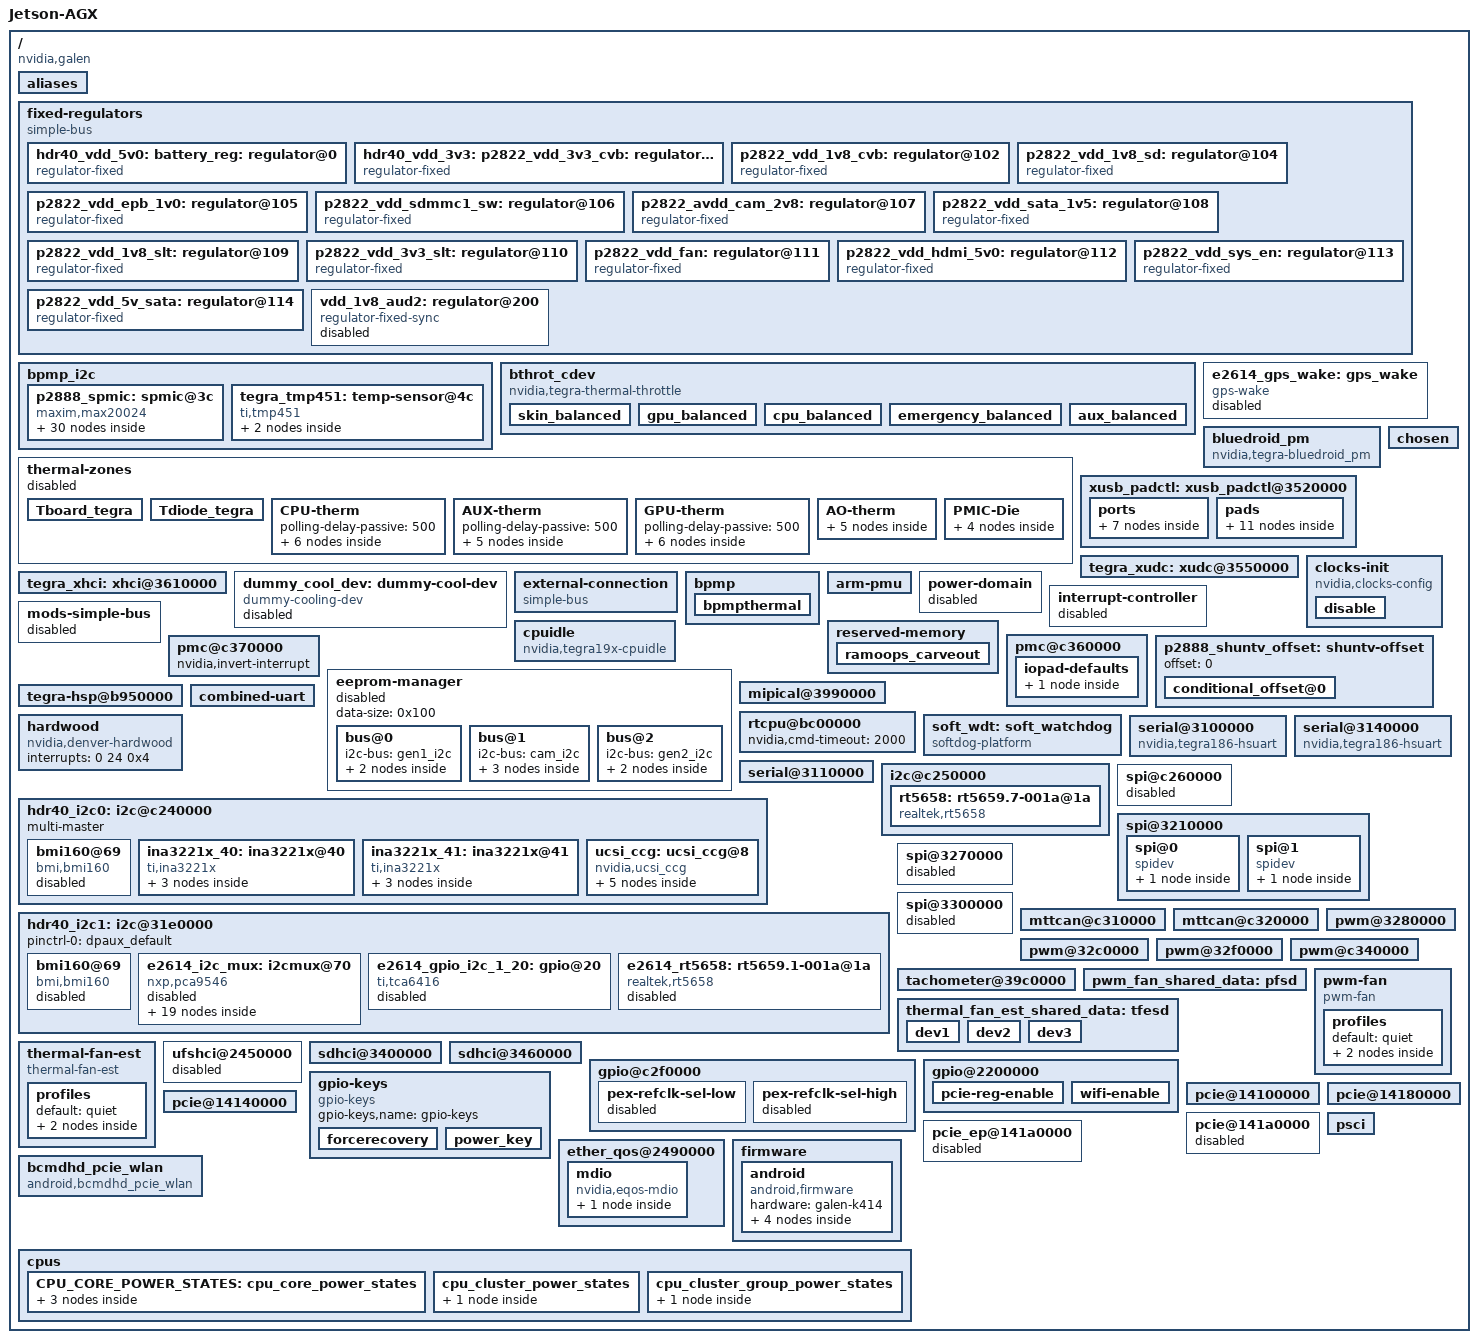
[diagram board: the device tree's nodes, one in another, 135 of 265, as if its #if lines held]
/*
 * Common include DTS file for CVM:P2888-0001 and CVB:P2822-0000 variants.
 *
 * Copyright (c) 2018-2020, NVIDIA CORPORATION.  All rights reserved.
 *
 * This program is free software; you can redistribute it and/or modify
 * it under the terms of the GNU General Public License as published by
 * the Free Software Foundation; version 2 of the License.
 *
 * This program is distributed in the hope that it will be useful, but WITHOUT
 * ANY WARRANTY; without even the implied warranty of MERCHANTABILITY or
 * FITNESS FOR A PARTICULAR PURPOSE.  See the GNU General Public License for
 * more details.
 */

#define TEMP_ALERT TEGRA194_MAIN_GPIO(H, 2)

#include <dt-bindings/types.h>
#include "dt-bindings/extcon-ids.h"
#include <dt-bindings/regulator/regulator.h>
#include "dt-bindings/gpio/tegra194-gpio.h"
#include <dt-bindings/clock/tegra194-clock.h>
#include <dt-bindings/pwm/pwm.h>
#include <dt-bindings/interrupt-controller/arm-gic.h>
#include <dt-bindings/interrupt-controller/irq.h>
#include <dt-bindings/thermal/thermal.h>
#include <dt-bindings/thermal/nvidia,tegra-thermal-throttle.h>
#include "dt-bindings/input/input.h"
#include <dt-bindings/display/tegra-dc.h>
#include <dt-bindings/display/tegra-panel.h>
#include <dt-bindings/mfd/max77620.h>
#include <dt-bindings/sound/rt5659.h>

/dts-v1/;

/memreserve/ 0x80000000 0x00010000;

#include <tegra194-soc/tegra194-soc-cvm.dtsi>

/ {
	model = "Jetson-AGX";
	compatible = "nvidia,tegra194";
	
	nvidia,dtsfilename = __FILE__;
	nvidia,dtbbuildtime = __DATE__, __TIME__;
	nvidia,fastboot-usb-vid = <0x0955>;
	nvidia,fastboot-usb-pid = <0xee1e>;
	model = "Jetson-AGX";
	compatible = "nvidia,galen", "nvidia,jetson-xavier", "nvidia,p2822-0000+p2888-0001", "nvidia,tegra194";

	#address-cells = <2>;
	#size-cells = <2>;

    aliases {
            rtc0 = &p2888_spmic;
            rtc1 = &tegra_rtc;
    };

	fixed-regulators {
		compatible = "simple-bus";
		device_type = "fixed-regulators";
		#address-cells = <1>;
		#size-cells = <0>;
		
		hdr40_vdd_5v0: battery_reg: regulator@0 {
			compatible = "regulator-fixed";
			reg = <0>;
			regulator-name = "vdd-ac-bat";
			regulator-min-microvolt = <5000000>;
			regulator-max-microvolt = <5000000>;
			regulator-always-on;
		};
		
		hdr40_vdd_3v3: p2822_vdd_3v3_cvb: regulator@101 {
			compatible = "regulator-fixed";
			reg = <101>;
			regulator-name = "vdd-3v3-cvb";
			regulator-min-microvolt = <3300000>;
			regulator-max-microvolt = <3300000>;
		};

		p2822_vdd_1v8_cvb: regulator@102 {
			compatible = "regulator-fixed";
			reg = <102>;
			regulator-name = "vdd-1v8-cvb";
			regulator-min-microvolt = <1800000>;
			regulator-max-microvolt = <1800000>;
		};

		p2822_vdd_1v8_sd: regulator@104 {
			compatible = "regulator-fixed";
			reg = <104>;
			regulator-name = "vdd-1v8-sd";
			regulator-min-microvolt = <1800000>;
			regulator-max-microvolt = <1800000>;
			gpio = <&tegra_main_gpio TEGRA194_MAIN_GPIO(A, 0) 0>;
			enable-active-high;
		};

		p2822_vdd_epb_1v0: regulator@105 {
			compatible = "regulator-fixed";
			reg = <105>;
			regulator-name = "vdd-epb-1v0";
			regulator-min-microvolt = <1000000>;
			regulator-max-microvolt = <1000000>;
			vin-supply = <&p2822_vdd_3v3_cvb>;
		};

		p2822_vdd_sdmmc1_sw: regulator@106 {
			compatible = "regulator-fixed";
			reg = <106>;
			regulator-name = "vdd-sdmmc1-sw";
			regulator-min-microvolt = <3300000>;
			regulator-max-microvolt = <3300000>;
			gpio = <&tegra_main_gpio TEGRA194_MAIN_GPIO(A, 0) 0>;
			enable-active-high;
		};

		p2822_avdd_cam_2v8: regulator@107 {
			compatible = "regulator-fixed";
			reg = <107>;
			regulator-name = "avdd-cam-2v8";
			regulator-min-microvolt = <2800000>;
			regulator-max-microvolt = <2800000>;
			gpio = <&tegra_main_gpio TEGRA194_MAIN_GPIO(N, 0) 0>;
			enable-active-high;
		};

		p2822_vdd_sata_1v5: regulator@108 {
			compatible = "regulator-fixed";
			reg = <108>;
			regulator-name = "vdd-sata-1v5";
			regulator-min-microvolt = <1500000>;
			regulator-max-microvolt = <1500000>;
		};

		p2822_vdd_1v8_slt: regulator@109 {
			compatible = "regulator-fixed";
			reg = <109>;
			regulator-name = "vdd-1v8-slt";
			regulator-min-microvolt = <1800000>;
			regulator-max-microvolt = <1800000>;
		};

		p2822_vdd_3v3_slt: regulator@110 {
			compatible = "regulator-fixed";
			reg = <110>;
			regulator-name = "vdd-3v3-slt";
			regulator-min-microvolt = <3300000>;
			regulator-max-microvolt = <3300000>;
		};

		p2822_vdd_fan: regulator@111 {
			compatible = "regulator-fixed";
			reg = <111>;
			regulator-name = "vdd-fan";
			regulator-min-microvolt = <5000000>;
			regulator-max-microvolt = <5000000>;
		};

		p2822_vdd_hdmi_5v0: regulator@112 {
			compatible = "regulator-fixed";
			reg = <112>;
			regulator-name = "vdd-hdmi-5v0";
			regulator-min-microvolt = <5000000>;
			regulator-max-microvolt = <5000000>;
			gpio = <&tegra_main_gpio TEGRA194_MAIN_GPIO(A, 3) 0>;
			enable-active-high;
		};

		p2822_vdd_sys_en: regulator@113 {
			compatible = "regulator-fixed";
			reg = <113>;
			regulator-name = "vdd_sys_en";
			regulator-min-microvolt = <1200000>;
			regulator-max-microvolt = <1200000>;
			gpio = <&tegra_main_gpio TEGRA194_MAIN_GPIO(M, 5) 0>;
			enable-active-high;
		};

		p2822_vdd_5v_sata: regulator@114 {
			compatible = "regulator-fixed";
			reg = <114>;
			regulator-name = "vdd-5v-sata";
			regulator-min-microvolt = <5000000>;
			regulator-max-microvolt = <5000000>;
			gpio = <&tegra_main_gpio TEGRA194_MAIN_GPIO(Z, 1) 0>;
			enable-active-high;
			vin-supply = <&battery_reg>;
		};
		
		vdd_1v8_aud2: regulator@200 {
			compatible = "regulator-fixed-sync";
			reg = <200>;
			regulator-name = "vdd-1v8-aud2";
			regulator-min-microvolt = <1800000>;
			regulator-max-microvolt = <1800000>;
			gpio = <&e2614_gpio_i2c_1_20 11 1>; /*DSPK EN*/
			enable-active-high;
			status = "disabled";
		};

	};

	bpmp_i2c {
		p2888_spmic: spmic@3c {
			compatible = "maxim,max20024";
			reg = <0x3c>;

			interrupt-parent = <&tegra_pm_irq>;
			interrupts = <0 TEGRA194_IRQ_PMIC_EXT_INTR IRQ_TYPE_NONE>;

			#interrupt-cells = <2>;
            interrupt-controller;

			gpio-controller;
			#gpio-cells = <2>;

			enable-clock32k-out;

			system-pmic-power-off;
			avoid-power-off-commands;

			hot-die-threshold-temp = <110000>;
			#thermal-sensor-cells = <0>;

			pinctrl-names = "default";
			pinctrl-0 = <&spmic_default>;

			spmic_default: pinmux@0 {
				pin_gpio0 {
					pins = "gpio0";
					function = "gpio";
				};

				pin_gpio1 {
					pins = "gpio1";
					function = "fps-out";
					active-fps-source = <MAX77620_FPS_SRC_DEF>;
				};

				pin_gpio2 {
					pins = "gpio2";
					function = "fps-out";
					active-fps-source = <MAX77620_FPS_SRC_DEF>;
				};

				pin_gpio3 {
					pins = "gpio3";
					function = "fps-out";
					active-fps-source = <MAX77620_FPS_SRC_DEF>;
				};

				pin_gpio4 {
					pins = "gpio4";
					function = "32k-out1";
					drive-push-pull = <1>;
				};

				pin_gpio6 {
					pins = "gpio6";
					function = "gpio";
					drive-push-pull = <1>;
				};

				pin_gpio7 {
					pins = "gpio7";
					function = "gpio";
					drive-push-pull = <0>;
				};
			};

			gpio_default {
				gpio-hog;
				output-high;
				gpios = <6 0 7 0>;
				label = "spmic-gpio6", "spmic-gpio7";
			};

			p2888_spmic_wdt: watchdog {
				wdt-boot-timeout = <32>;
				wdt-suspend-timeout = <120>;
				status = "disabled";
			};

			fps {
				#address-cells = <1>;
				#size-cells = <0>;

				fps0 {
					reg = <0>;
					fps-event-source = <MAX77620_FPS_EVENT_SRC_EN0>;
				};

				fps1 {
					reg = <1>;
					fps-event-source = <MAX77620_FPS_EVENT_SRC_EN1>;
					device-state-on-disabled-event = <MAX77620_FPS_INACTIVE_STATE_SLEEP>;
				};

				fps2 {
					reg = <2>;
					fps-event-source = <MAX77620_FPS_EVENT_SRC_EN0>;
				};
			};

			backup-battery {
				backup-battery-charging-current = <100>;
				backup-battery-charging-voltage = <3000000>;
				backup-battery-output-resister = <100>;
				status = "disabled";
			};

			regulators {
				in-ldo7-8-supply = <&p2888_spmic_sd2>;

				p2888_spmic_sd0: sd0 {
					regulator-name = "vdd-1v0";
					regulator-always-on;
					regulator-boot-on;
					regulator-init-mode = <REGULATOR_MODE_NORMAL>;
					active-fps-source = <MAX77620_FPS_SRC_DEF>;
					regulator-enable-ramp-delay = <3960>;
					regulator-disable-ramp-delay = <660>;
					ramp-rate-setting = <27500>;
					regulator-ramp-delay = <1100>;
				};

				p2888_spmic_sd1: sd1 {
					regulator-name = "vdd-1v8-hs";
					regulator-always-on;
					regulator-boot-on;
					regulator-init-mode = <REGULATOR_MODE_NORMAL>;
					active-fps-source = <MAX77620_FPS_SRC_DEF>;
					regulator-enable-ramp-delay = <3310>;
					regulator-disable-ramp-delay = <2000>;
					ramp-rate-setting = <27500>;
					regulator-ramp-delay = <550>;
				};

				p2888_spmic_sd2: sd2 {
					regulator-name = "vdd-1v8-ls";
					regulator-always-on;
					regulator-boot-on;
					regulator-init-mode = <REGULATOR_MODE_NORMAL>;
					active-fps-source = <MAX77620_FPS_SRC_DEF>;
					regulator-enable-ramp-delay = <3310>;
					regulator-disable-ramp-delay = <1970>;
					ramp-rate-setting = <27500>;
					regulator-ramp-delay = <550>;
				};

				p2888_spmic_sd3: sd3 {
					regulator-name = "vdd-1v8-ao";
					regulator-always-on;
					regulator-boot-on;
					regulator-init-mode = <REGULATOR_MODE_NORMAL>;
					active-fps-source = <MAX77620_FPS_SRC_DEF>;
					regulator-enable-ramp-delay = <2130>;
					regulator-disable-ramp-delay = <1970>;
					ramp-rate-setting = <27500>;
					regulator-ramp-delay = <350>;
				};

				p2888_spmic_sd4: sd4 {
					regulator-name = "vddio-ddr-1v1";
					regulator-always-on;
					regulator-boot-on;
					regulator-init-mode = <REGULATOR_MODE_NORMAL>;
					active-fps-source = <MAX77620_FPS_SRC_DEF>;
					regulator-enable-ramp-delay = <2650>;
					regulator-disable-ramp-delay = <1300>;
					ramp-rate-setting = <27500>;
					regulator-ramp-delay = <700>;
				};

				p2888_spmic_ldo0: ldo0 {
					regulator-name = "vdd-rtc";
					regulator-always-on;
					regulator-boot-on;
					active-fps-source = <MAX77620_FPS_SRC_DEF>;
					regulator-enable-ramp-delay = <160>;
					regulator-disable-ramp-delay = <4480>;
					ramp-rate-setting = <100000>;
					regulator-ramp-delay = <200>;
				};

				p2888_spmic_ldo1: ldo1 {
					regulator-name = "spmic-ldo1";
					active-fps-source = <MAX77620_FPS_SRC_DEF>;
					regulator-enable-ramp-delay = <2650>;
					regulator-disable-ramp-delay = <1300>;
					ramp-rate-setting = <100000>;
					regulator-ramp-delay = <1150>;
				};

				p2888_spmic_ldo2: ldo2 {
					regulator-name = "vdd-ao-3v3";
					regulator-always-on;
					regulator-boot-on;
					active-fps-source = <MAX77620_FPS_SRC_DEF>;
					regulator-enable-ramp-delay = <4670>;
					ramp-rate-setting = <100000>;
					regulator-ramp-delay = <1500>;
				};

				p2888_spmic_ldo3: ldo3 {
					regulator-name = "vddio-emmc-3v3";
					regulator-always-on;
					regulator-boot-on;
					active-fps-source = <MAX77620_FPS_SRC_DEF>;
					regulator-enable-ramp-delay = <4670>;
					ramp-rate-setting = <100000>;
					regulator-ramp-delay = <1500>;
				};

				p2888_spmic_ldo4: ldo4 {
					regulator-name = "spmic-ldo4";
					active-fps-source = <MAX77620_FPS_SRC_DEF>;
					regulator-enable-ramp-delay = <3310>;
					regulator-disable-ramp-delay = <1970>;
					ramp-rate-setting = <100000>;
					regulator-ramp-delay = <2200>;
				};

				p2888_spmic_ldo5: ldo5 {
					regulator-name = "vdd-usb-3v3";
					regulator-always-on;
					regulator-boot-on;
					active-fps-source = <MAX77620_FPS_SRC_DEF>;
					regulator-enable-ramp-delay = <4670>;
					ramp-rate-setting = <100000>;
					regulator-ramp-delay = <1500>;
				};

				p2888_spmic_ldo6: ldo6 {
					regulator-name = "vddio-sdmmc1-3v3";
					regulator-always-on;
					regulator-boot-on;
					active-fps-source = <MAX77620_FPS_SRC_DEF>;
					regulator-enable-ramp-delay = <4690>;
					ramp-rate-setting = <100000>;
					regulator-ramp-delay = <1500>;
				};

				p2888_spmic_ldo7: ldo7 {
					regulator-name = "vdd-csi-1v2";
					regulator-always-on;
					regulator-boot-on;
					active-fps-source = <MAX77620_FPS_SRC_DEF>;
					regulator-enable-ramp-delay = <3960>;
					regulator-disable-ramp-delay = <660>;
					ramp-rate-setting = <100000>;
					regulator-ramp-delay = <3350>;
				};

				p2888_spmic_ldo8: ldo8 {
					regulator-name = "spmic-ldo8";
					active-fps-source = <MAX77620_FPS_SRC_DEF>;
					regulator-enable-ramp-delay = <3960>;
					regulator-disable-ramp-delay = <660>;
					ramp-rate-setting = <100000>;
					regulator-ramp-delay = <2250>;
				};
				
			};
		};

		tegra_tmp451: temp-sensor@4c {
			status = "okay";
			#thermal-sensor-cells = <1>;
			compatible = "ti,tmp451";
			reg = <0x4c>;
			sensor-name = "tmp451-ext";
			supported-hwrev = <1>;
			offset = <(-38)>;
			conv-rate = <0x06>;
			extended-rage = <1>;

			interrupt-parent = <&tegra_main_gpio>;
			interrupts = <TEMP_ALERT IRQ_TYPE_LEVEL_LOW>;
			temp-alert-gpio = <&tegra_main_gpio TEMP_ALERT 0>;

			vdd-supply = <&p2822_vdd_1v8_slt>;

			/* vdd-supply configured in power tree */

			loc {
				/* set to maximum for not having local  shutdown */
				shutdown-limit = <107>;
			};
			ext {
				shutdown-limit = <109>;
			};
		};
	};

	bthrot_cdev {
		compatible = "nvidia,tegra-thermal-throttle";
		clocks = <&bpmp_clks TEGRA194_CLK_NAFLL_CLUSTER0>,
				<&bpmp_clks TEGRA194_CLK_NAFLL_CLUSTER1>,
				<&bpmp_clks TEGRA194_CLK_NAFLL_CLUSTER2>,
				<&bpmp_clks TEGRA194_CLK_NAFLL_CLUSTER3>,
				<&bpmp_clks TEGRA194_CLK_NAFLL_GPU>;
		clock-names = "cpu0", "cpu1", "cpu2", "cpu3", "gpu";
		skin_balanced {
			cdev-type = "skin-balanced";
			#cooling-cells = <2>;
			nvidia,throttle-clocks = <TEGRA_THROTTLE_CPU 200 0
						TEGRA_THROTTLE_GPU 400 0>;
		};
		gpu_balanced {
			cdev-type = "gpu-balanced";
			#cooling-cells = <2>;
			nvidia,cutoff = <1>;
			nvidia,throttle-clocks = <TEGRA_THROTTLE_CPU 400 0
						TEGRA_THROTTLE_GPU 400 0>;
		};
		cpu_balanced {
			cdev-type = "cpu-balanced";
			#cooling-cells = <2>;
			nvidia,throttle-clocks = <TEGRA_THROTTLE_CPU 200 0
						TEGRA_THROTTLE_GPU 300 365500000>;
		};
		emergency_balanced {
			cdev-type = "emergency-balanced";
			#cooling-cells = <2>;
			nvidia,throttle-clocks = <TEGRA_THROTTLE_CPU 10 38400000
						TEGRA_THROTTLE_GPU 10 25500000>;
		};
		aux_balanced {
			cdev-type = "aux-balanced";
			#cooling-cells = <2>;
			nvidia,cutoff = <1>;
			nvidia,throttle-clocks = <TEGRA_THROTTLE_CPU 400 0
						TEGRA_THROTTLE_GPU 400 0>;
		};
	};
	
	thermal-zones {
		status = "disabled";

		Tboard_tegra: Tboard_tegra {
			status = "okay";
			polling-delay = <0>;
			polling-delay-passive = <1000>;
			thermal-sensors = <&tegra_tmp451 0>;
		};

		Tdiode_tegra: Tdiode_tegra {
			status = "okay";
			polling-delay = <0>;
			polling-delay-passive = <1000>;
			thermal-sensors = <&tegra_tmp451 1>;
		};
		
		CPU-therm {
			status = "okay";
			polling-delay-passive = <500>;

			thermal-zone-params {
				governor-name = "step_wise";
			};

			trips {
				trip_critical {
					temperature = <95500>;
					type = "critical";
					hysteresis = <0>;
					writable;
				};
				trip_bthrot {
					temperature = <90000>;
					type = "passive";
					hysteresis = <0>;
					writable;
				};
			};
			cooling-maps {
				map0 {
					trip = <&{/thermal-zones/CPU-therm/trips/trip_bthrot}>;
					cdev-type = "cpu-balanced";
					cooling-device = <&{/bthrot_cdev/cpu_balanced} THERMAL_NO_LIMIT THERMAL_NO_LIMIT>;
				};
			};
			
			trips {
				MAKE_EQOS_TRIP(m40, -40000, 5000);
				MAKE_EQOS_TRIP(m5, -5000, 5000);
				MAKE_EQOS_TRIP(p30, 30000, 5000);
				MAKE_EQOS_TRIP(p65, 65000, 5000);
				MAKE_EQOS_TRIP(p100, 100000, 5000);
			};

			cooling-maps {
				MAP_EQOS(m40, 1);
				MAP_EQOS(m5, 2);
				MAP_EQOS(p30, 3);
				MAP_EQOS(p65, 4);
				MAP_EQOS(p100, 5);
			};
			
		};

		AUX-therm {
			status = "okay";
			polling-delay-passive = <500>;
			trips {
				trip_critical {
					temperature = <94500>;
					type = "critical";
					hysteresis = <0>;
					writable;
				};

				trip_bthrot {
					temperature = <89000>;
					type = "passive";
					hysteresis = <0>;
					writable;
				};
			};
			cooling-maps {
				map0 {
					trip = <&{/thermal-zones/AUX-therm/trips/trip_bthrot}>;
					cdev-type = "aux-balanced";
					cooling-device = <&{/bthrot_cdev/aux_balanced} THERMAL_NO_LIMIT THERMAL_NO_LIMIT>;
				};
			};
		};

		GPU-therm {
			status = "okay";
			polling-delay-passive = <500>;

			thermal-zone-params {
				governor-name = "step_wise";
			};

			trips {
				trip_critical {
					temperature = <98000>;
					type = "critical";
					hysteresis = <0>;
					writable;
				};
				trip_bthrot {
					temperature = <92500>;
					type = "passive";
					hysteresis = <0>;
					writable;
				};
			};
			cooling-maps {
				map0 {
					trip = <&{/thermal-zones/GPU-therm/trips/trip_bthrot}>;
					cdev-type = "gpu-balanced";
					cooling-device = <&{/bthrot_cdev/gpu_balanced} THERMAL_NO_LIMIT THERMAL_NO_LIMIT>;
				};
			};

		};

		AO-therm {
			status = "okay";

			thermal-zone-params {
				governor-name = "step_wise";
			};

			trips {
				trip_dram_refresh {
					temperature = <85000>;
					type = "active";
					hysteresis = <3000>;
					writable;
				};
			};
			cooling-maps {
				map0 {
					trip = <&{/thermal-zones/AO-therm/trips/trip_dram_refresh}>;
					cdev-type = "bwmgr-therm-handler";
					cooling-device = <&bwmgr THERMAL_NO_LIMIT THERMAL_NO_LIMIT>;
				};
			};
		};
		
		PMIC-Die {
			polling-delay = <0>; /* milliseconds */
			polling-delay-passive = <0>; /* milliseconds */

			thermal-sensors = <&p2888_spmic>;
			trips {
				die_temp_thresh: hot-die {
					temperature = <120000>;
					type = "active";
					hysteresis = <0>;
				};
			};

			cooling-maps {
				map0 {
					trip = <&die_temp_thresh>;
					cooling-device = <&{/bthrot_cdev/emergency_balanced}
							THERMAL_NO_LIMIT THERMAL_NO_LIMIT>;
					contribution = <100>;
					cdev-type = "emergency-balanced";
				};
			};
		};
		
	};

	e2614_gps_wake: gps_wake {
		compatible = "gps-wake";
		gps-enable-gpio = <&e2614_gpio_i2c_1_20 8 0>;
		gps-wakeup-gpio = <&tegra_main_gpio TEGRA194_AON_GPIO(AA, 0) 0>;
		status = "disabled";
	};

	bluedroid_pm {
		compatible = "nvidia,tegra-bluedroid_pm";
		bluedroid_pm,reset-gpio = <&tegra_main_gpio TEGRA194_MAIN_GPIO(M, 6) 0>;
		bluedroid_pm,host-wake-gpio = <&tegra_main_gpio TEGRA194_MAIN_GPIO(Y, 0) 0>;
		bluedroid_pm,ext-wake-gpio = <&tegra_main_gpio TEGRA194_MAIN_GPIO(M, 7) 0>;
		interrupt-parent = <&tegra_main_gpio>;
		interrupts = <TEGRA194_MAIN_GPIO(Y, 0) 0x01>;
	};

#if TEGRA_XUSB_PADCONTROL_VERSION >= DT_VERSION_2
	xusb_padctl: xusb_padctl@3520000 {
		status = "okay";
		pex_dvdd-supply = <&p2888_spmic_sd0>;
		pex_hvdd-supply = <&p2888_spmic_sd1>;
		pex_pll_hvdd-supply = <&p2888_spmic_sd1>;
		vclamp_usb-supply = <&p2888_spmic_sd3>;
		avdd_usb-supply = <&p2888_spmic_ldo5>;
		avdd_pll_nvhs_eutmip-supply = <&p2888_spmic_sd1>;
		ports {
			usb2-0 {
				vbus-supply = <&battery_reg>;
			};
			usb2-1 {
				vbus-supply = <&battery_reg>;
			};
			usb2-2 {
				vbus-supply = <&battery_reg>;
			};
			usb2-3 {
				vbus-supply = <&p2822_vdd_5v_sata>;
			};
		};
		
		pads {
			usb2 {
				lanes {
					usb2-0 {
						nvidia,function = "xusb";
						status = "okay";
					};
					usb2-1 {
						nvidia,function = "xusb";
						status = "okay";
					};
					usb2-2 {
						nvidia,function = "xusb";
						status = "okay";
					};
					usb2-3 {
						nvidia,function = "xusb";
						status = "okay";
					};
				};
			};
			usb3 {
				lanes {
					usb3-0 {
						nvidia,function = "xusb";
						status = "okay";
					};
					usb3-2 {
						nvidia,function = "xusb";
						status = "okay";
					};
					usb3-3 {
						nvidia,function = "xusb";
						status = "okay";
					};
				};
			};
		};

		ports {
			usb2-0 {
				mode = "otg";
				status = "okay";
			};
			usb2-1 {
				mode = "host";
				status = "okay";
			};
			usb2-2 {
				mode = "host";
				status = "okay";
			};
			usb2-3 {
				mode = "host";
				status = "okay";
			};
			usb3-0 {
				nvidia,usb2-companion = <1>;
				status = "okay";
			};
			usb3-2 {
				nvidia,usb2-companion = <0>;
				status = "okay";
			};
			usb3-3 {
				nvidia,usb2-companion = <3>;
				nvidia,usb3-gen1-only= <1>;
				status = "okay";
			};
		};
	};
#endif

	tegra_xudc: xudc@3550000 {
		avdd-usb-supply = <&p2888_spmic_ldo5>;
		extcon-cables = <&typec_port0 0>;
		extcon-cable-names = "vbus";
		#extcon-cells = <1>;
#if TEGRA_XUSB_PADCONTROL_VERSION >= DT_VERSION_2
		phys = <&{/xusb_padctl@3520000/pads/usb2/lanes/usb2-0}>,
			<&{/xusb_padctl@3520000/pads/usb3/lanes/usb3-2}>;
		phy-names = "usb2", "usb3";
		nvidia,xusb-padctl = <&xusb_padctl>;
#endif
		nvidia,boost_cpu_freq = <1200>;
		status = "okay";
	};

	tegra_xhci: xhci@3610000 {
		extcon-cables = <&typec_port0 1>;
		extcon-cable-names = "id";
		#extcon-cells = <1>;
#if TEGRA_XUSB_PADCONTROL_VERSION >= DT_VERSION_2
		phys = <&{/xusb_padctl@3520000/pads/usb2/lanes/usb2-0}>,
			<&{/xusb_padctl@3520000/pads/usb2/lanes/usb2-1}>,
			<&{/xusb_padctl@3520000/pads/usb2/lanes/usb2-3}>,
			<&{/xusb_padctl@3520000/pads/usb2/lanes/usb2-2}>,
			<&{/xusb_padctl@3520000/pads/usb3/lanes/usb3-2}>,
			<&{/xusb_padctl@3520000/pads/usb3/lanes/usb3-0}>,
			<&{/xusb_padctl@3520000/pads/usb3/lanes/usb3-3}>;
		phy-names = "usb2-0", "usb2-1", "usb2-3", "usb2-2",
			"usb3-2", "usb3-0", "usb3-3";
		nvidia,xusb-padctl = <&xusb_padctl>;
#endif
		status = "okay";
	};
	
	chosen {
		bootargs ="console=ttyTCU0,115200";
		board-has-eeprom;
	};
	
	clocks-init {
		compatible = "nvidia,clocks-config";
		status = "okay";
		disable {
			clocks = <&aon_clks TEGRA194_CLK_PLLAON>,
				<&bpmp_clks TEGRA194_CLK_CAN1>,
				<&bpmp_clks TEGRA194_CLK_CAN2>;
		};
	};

	dummy_cool_dev: dummy-cool-dev {
		compatible = "dummy-cooling-dev";
		#cooling-cells = <2>; /* min followed by max */
		status = "disabled";
	};

	external-connection {
		compatible = "simple-bus";
		device_type = "external-connection";
		#address-cells = <1>;
		#size-cells = <0>;
	};

	bpmp {
		bpmpthermal {
			status = "okay";
		};
	};

	arm-pmu {
		status = "okay";
	};

	power-domain {
		status = "disabled";
	};

	interrupt-controller {
		status = "disabled";
	};

	mods-simple-bus {
		status = "disabled";
	};

	cpuidle {
		compatible = "nvidia,tegra19x-cpuidle";
		status = "okay";
	};

	reserved-memory {
		ramoops_carveout {
			status = "okay";
		};
	};

	/* Power Management Controller */
	pmc@c360000 {
		iopad-defaults {
			sdmmc-io-pads {
				pins = "sdmmc1-hv", "sdmmc3-hv";
				nvidia,enable-voltage-switching;
			};
		};
	};

	pmc@c370000 {
		nvidia,invert-interrupt;
	};

	eeprom-manager {
		status = "disabled";
		data-size = <0x100>;
		bus@0 {
			i2c-bus = <&gen1_i2c>;
			eeprom@0 {
				slave-address = <0x50>;
				label = "cvm";
			};
			eeprom@1 {
				slave-address = <0x56>;
			};
		};
		bus@1 {
			i2c-bus = <&cam_i2c>;
			eeprom@0 {
				slave-address = <0x54>;
			};
			eeprom@1 {
				slave-address = <0x57>;
			};
			eeprom@2 {
				slave-address = <0x52>;
			};
		};
		bus@2 {
			i2c-bus = <&gen2_i2c>;
			eeprom@0 {
				slave-address = <0x52>;
				label = "cvm";
			};
			eeprom@1 {
				slave-address = <0x50>;
			};
		};
		
	};

	p2888_shuntv_offset: shuntv-offset {
		offset = <0>;
		conditional_offset@0 {
			shunt_volt_start = <0xFFFFFFD8>;
			shunt_volt_end = <0xFFFFFFD8>;
			offset = <40>;
		};
	};

	mipical@3990000 {
		status = "okay";
	};

	tegra-hsp@b950000 {
		status = "okay";
	};

	rtcpu@bc00000 {
		status = "okay";
		nvidia,cmd-timeout = <2000>;
	};

	hardwood {
		compatible = "nvidia,denver-hardwood";
		interrupts = <0 24 0x4>;
	};

	soft_wdt:soft_watchdog {
		compatible = "softdog-platform";
		status = "okay";
	};
	
/* uart-configure */
	combined-uart {
		console-port;
		combined-uart;
		status = "okay";
	};
	
	serial@3100000 {
		compatible = "nvidia,tegra186-hsuart";
		status = "okay";
	};

	serial@3140000 {
		compatible = "nvidia,tegra186-hsuart";
		status = "okay";
	};

	serial@3110000 {
		status = "okay";
	};
	
	
/* i2c-configure */
	i2c@c250000 {
		rt5658: rt5659.7-001a@1a {
			compatible = "realtek,rt5658";
			reg = <0x1a>;

			realtek,jd-src = <RT5659_JD_NULL>;
			realtek,dmic1-data-pin = <RT5659_DMIC1_NULL>;
			realtek,dmic2-data-pin = <RT5659_DMIC2_NULL>;

			gpios = <&tegra_main_gpio TEGRA194_MAIN_GPIO(S, 5) 0>;

			status = "okay";
		};
	};
	
	hdr40_i2c0: i2c@c240000 {
		multi-master;
		
		bmi160@69 {
			compatible = "bmi,bmi160";
			reg = <0x69>;
			interrupt-parent = <&tegra_aon_gpio>;
			interrupts = <TEGRA194_AON_GPIO(AA, 2) GPIO_ACTIVE_LOW>;
			accelerometer_matrix    = [01 00 00 00 01 00 00 00 01];
			gyroscope_matrix        = [01 00 00 00 01 00 00 00 01];
			accelerometer_delay_us_min = <1250>;
			gyroscope_delay_us_min = <1250>;
			status = "disabled";
		};
		
		ina3221x_40: ina3221x@40 {
			compatible = "ti,ina3221x";
			reg = <0x40>;
			ti,trigger-config = <0x7003>;
			ti,continuous-config = <0x7c07>;
			ti,enable-forced-continuous;
			#address-cells = <1>;
			#size-cells = <0>;
			#io-channel-cells = <1>;
			channel@0 {
				reg = <0x0>;
				ti,rail-name = "GPU";
				ti,shunt-resistor-mohm = <5>;
				shunt-volt-offset-uv = <&p2888_shuntv_offset>;
			};
			channel@1 {
				reg = <0x1>;
				ti,rail-name = "CPU";
				ti,shunt-resistor-mohm = <5>;
				shunt-volt-offset-uv = <&p2888_shuntv_offset>;
			};
			channel@2 {
				reg = <0x2>;
				ti,rail-name = "SOC";
				ti,shunt-resistor-mohm = <5>;
				shunt-volt-offset-uv = <&p2888_shuntv_offset>;
			};
		};
		
		ina3221x_41: ina3221x@41 {
			compatible = "ti,ina3221x";
			reg = <0x41>;
			ti,trigger-config = <0x7003>;
			ti,continuous-config = <0x7c07>;
			ti,enable-forced-continuous;
			#address-cells = <1>;
			#size-cells = <0>;
			#io-channel-cells = <1>;
			channel@0 {
				reg = <0x0>;
				ti,rail-name = "CV";
				ti,shunt-resistor-mohm = <5>;
				shunt-volt-offset-uv = <&p2888_shuntv_offset>;
			};
			channel@1 {
				reg = <0x1>;
				ti,rail-name = "VDDRQ";
				ti,shunt-resistor-mohm = <5>;
				shunt-volt-offset-uv = <&p2888_shuntv_offset>;
			};
			channel@2 {
				reg = <0x2>;
				ti,rail-name = "SYS5V";
				ti,shunt-resistor-mohm = <5>;
				shunt-volt-offset-uv = <&p2888_shuntv_offset>;
			};
		};
		
		ucsi_ccg: ucsi_ccg@8 {
			compatible = "nvidia,ucsi_ccg";
			reg = <0x08>;
			ccg,irqflags = <IRQF_TRIGGER_LOW>;
			interrupt-parent = <&tegra_aon_gpio>;
			interrupts = <TEGRA194_AON_GPIO(BB, 2) 0>;
			wakeup-source;
			status = "okay";
			typec-extcon {
				typec_port0: port-0 {
					status = "okay";
					#extcon-cells = <1>;
				};
				typec_port1: port-1 {
					status = "okay";
					#extcon-cells = <1>;
				};
			};
			typec-pd {
				typec_pd: pd {
					status = "okay";
					#extcon-cells = <1>;
				};
			};
		};
	};

	hdr40_i2c1: i2c@31e0000 {
		pinctrl-names = "default";
		pinctrl-0 = <&dpaux_default>;
		
		bmi160@69 {
			compatible = "bmi,bmi160";
			reg = <0x69>;
			accelerometer_matrix    = [01 00 00 00 01 00 00 00 01];
			gyroscope_matrix        = [01 00 00 00 01 00 00 00 01];
			status = "disabled";
		};

		e2614_i2c_mux: i2cmux@70 {
			compatible = "nxp,pca9546";
			reg = <0x70>;
			#address-cells = <1>;
			#size-cells = <0>;
			vcc-pullup-supply = <&battery_reg>;
			status = "disabled";
			
			i2c@0 {
				reg = <0>;
				i2c-mux,deselect-on-exit;
				#address-cells = <1>;
				#size-cells = <0>;
				e2614_tas2552_r:tas2552.9-0040@40 {
					compatible = "ti,tas2552";
					reg = <0x40>;
					vbat-supply = <&battery_reg>;
					avdd-supply = <&vdd_1v8_aud2>;
					tas2552,pdm_edge_select = <0>;
				};
				e2614_tas2552_l:tas2552.9-0041@41 {
                                        compatible = "ti,tas2552";
                                        reg = <0x41>;
                                        vbat-supply = <&battery_reg>;
                                        avdd-supply = <&vdd_1v8_aud2>;
					tas2552,pdm_edge_select = <1>;
                                };
			};
			
			i2c@1 {
				reg = <1>;
				i2c-mux,deselect-on-exit;
				#address-cells = <1>;
				#size-cells = <0>;
				ina3221x@40 {
					compatible = "ti,ina3221x";
					reg = <0x40>;
					ti,trigger-config = <0x7003>;
					ti,continuous-config = <0x7c07>;
					ti,enable-forced-continuous;
					#address-cells = <1>;
					#size-cells = <0>;
					channel@0 {
						reg = <0x0>;
						ti,rail-name = "VDD_5V";
						ti,shunt-resistor-mohm = <10>;
					};
					channel@1 {
						reg = <0x1>;
						ti,rail-name = "VDD_3V3";
						ti,shunt-resistor-mohm = <10>;
					};
					channel@2 {
						reg = <0x2>;
						ti,rail-name = "VDD_1V8";
						ti,shunt-resistor-mohm = <1>;
					};
				};
				ina3221x@41 {
					compatible = "ti,ina3221x";
					reg = <0x41>;
					ti,trigger-config = <0x7003>;
					ti,continuous-config = <0x7c07>;
					ti,enable-forced-continuous;
					#address-cells = <1>;
					#size-cells = <0>;
					channel@0 {
						reg = <0x0>;
						ti,rail-name = "VDD_5V_AUD";
						ti,shunt-resistor-mohm = <1>;
					};
					channel@1 {
						reg = <0x1>;
						ti,rail-name = "VDD_3V3_AUD";
						ti,shunt-resistor-mohm = <10>;
					};
					channel@2 {
						reg = <0x2>;
						ti,rail-name = "VDD_1V8_AUD";
						ti,shunt-resistor-mohm = <10>;
					};
				};
				ina3221x@42 {
					compatible = "ti,ina3221x";
					reg = <0x42>;
					ti,trigger-config = <0x7003>;
					ti,continuous-config = <0x7c07>;
					ti,enable-forced-continuous;
					#address-cells = <1>;
					#size-cells = <0>;
					channel@0 {
						reg = <0x0>;
						ti,rail-name = "VDD_3V3_GPS";
						ti,shunt-resistor-mohm = <10>;
					};
					channel@1 {
						reg = <0x1>;
						ti,rail-name = "VDD_3V3_NFC";
						ti,shunt-resistor-mohm = <10>;
					};
					channel@2 {
						reg = <0x2>;
						ti,rail-name = "VDD_3V3_GYRO";
						ti,shunt-resistor-mohm = <10>;
					};
				};
			};
			
			i2c@2 {
				reg = <2>;
				i2c-mux,deselect-on-exit;
				#address-cells = <1>;
				#size-cells = <0>;
			};
			
			i2c@3 {
				reg = <3>;
				i2c-mux,deselect-on-exit;
				#address-cells = <1>;
				#size-cells = <0>;
				e2614_rt5658_i2c3: rt5659.12-001a@1a {
					compatible = "realtek,rt5658";
					reg = <0x1a>;
					status = "disabled";

					/* gpio for jack detection */
					gpios = <&tegra_main_gpio TEGRA194_MAIN_GPIO(R, 0) 0>;

					/* refer include/sound/rt5659.h for the values to be used */
					realtek,jd-src = <1>; /* RT5659_JD3 */
					realtek,dmic1-data-pin = <2>; /* RT5659_DMIC1_DATA_GPIO5 */
				};
			};
		};

		e2614_gpio_i2c_1_20: gpio@20 {
			compatible = "ti,tca6416";
			reg = <0x20>;
			gpio-controller;
			#gpio-cells = <2>;
			vcc-supply = <&battery_reg>;
			status = "disabled";
		};

		e2614_rt5658: rt5659.1-001a@1a {
			compatible = "realtek,rt5658";
			reg = <0x1a>;
			status = "disabled";

			/* gpio for jack detection */
			gpios = <&tegra_main_gpio TEGRA194_MAIN_GPIO(R, 0) 0>;

			/* refer include/sound/rt5659.h for the values to be used */
			realtek,jd-src = <1>; /* RT5659_JD3 */
			realtek,dmic1-data-pin = <2>; /* RT5659_DMIC1_DATA_GPIO5 */
		};

		i2cmux@70 {
			vcc-supply = <&p2822_vdd_3v3_cvb>;
			i2c@0 {
				tas2552.9-0040@40 {
					iovdd-supply = <&p2822_vdd_3v3_cvb>;
				};
				tas2552.9-0041@41 {
					iovdd-supply = <&p2822_vdd_3v3_cvb>;
                                };
			};
		};

	};
	
/* spi-configure */
	spi@c260000 {
        clocks = <&bpmp_clks TEGRA194_CLK_SPI2>,
                 <&bpmp_clks TEGRA194_CLK_OSC>;
		status = "disabled";
	};

	spi@3210000 {
		status = "okay";
		spi@0 {
			compatible = "spidev";
			reg = <0x0>;
			spi-max-frequency = <33000000>;
			controller-data {
				nvidia,enable-hw-based-cs;
				nvidia,rx-clk-tap-delay = <0x11>;
			};
		};
		spi@1 {
			compatible = "spidev";
			reg = <0x1>;
			spi-max-frequency = <33000000>;
			controller-data {
				nvidia,enable-hw-based-cs;
				nvidia,rx-clk-tap-delay = <0x11>;
			};
		};
	};

	spi@3270000 {
		status = "disabled";
	};

	spi@3300000 {
		status = "disabled";
	};

/* can-configure */
    mttcan@c310000 {
		pll_source = "osc";
            clocks = <&bpmp_clks TEGRA194_CLK_CAN1_CORE>,
                    <&bpmp_clks TEGRA194_CLK_CAN1_HOST>,
                    <&bpmp_clks TEGRA194_CLK_CAN1>,
                    <&bpmp_clks TEGRA194_CLK_OSC>;
	 clock-names = "can_core", "can_host","can", "osc";
	 status = "okay";
    };

    mttcan@c320000 {
		pll_source = "osc";
            clocks = <&bpmp_clks TEGRA194_CLK_CAN2_CORE>,
                    <&bpmp_clks TEGRA194_CLK_CAN2_HOST>,
                    <&bpmp_clks TEGRA194_CLK_CAN2>,
                    <&bpmp_clks TEGRA194_CLK_OSC>;
		clock-names = "can_core", "can_host","can", "osc";
		status = "okay";
    };
	
/* pwm-configure */
	pwm@3280000 {
		status = "okay";
	};

	pwm@32c0000 {
		status = "okay";
	};

	pwm@32f0000 {
		status = "okay";
	};
	
	pwm@c340000 {
		status = "okay";
	};

	tachometer@39c0000 {
		status = "okay";
	};

	pwm_fan_shared_data: pfsd {
		num_resources = <0>;
		secret = <47>;
		active_steps = <10>;
		active_rpm = <0 1000 2000 3000 4000 5000 6000 7000 10000 11000>;
		rpm_diff_tolerance = <2>;
		active_rru = <40 2 1 1 1 1 1 1 1 1>;
		active_rrd = <40 2 1 1 1 1 1 1 1 1>;
		state_cap_lookup = <2 2 2 2 3 3 3 4 4 4>;
		pwm_period = <45334>;
		pwm_id = <4>;
		pwm_polarity = <PWM_POLARITY_NORMAL>;
		suspend_state = <0>;
		step_time = <100>; /* mesecs */
		state_cap = <7>;
		active_pwm_max = <256>;
		tach_period = <1000>;
		pwm_gpio = <&tegra_aon_gpio TEGRA194_AON_GPIO(CC, 4) GPIO_ACTIVE_LOW>;
	};

	pwm-fan {
		compatible = "pwm-fan";
		status = "okay";
		#pwm-cells = <1>;
		pwms = <&tegra_pwm4 0 45334>;
		vdd-fan-supply = <&p2822_vdd_fan>;
		shared_data = <&pwm_fan_shared_data>;
		profiles {
			default = "quiet";
			quiet {
				state_cap = <4>;
				active_pwm = <0 77 120 160 255 255 255 255 255 255>;
			};
			cool {
				state_cap = <4>;
				active_pwm = <0 77 120 160 255 255 255 255 255 255>;
			};
		};
	};

	thermal_fan_est_shared_data: tfesd {
		secret = <37>;
		toffset = <0>;
		polling_period = <1100>;
		ndevs = <3>;
		cdev_type = "pwm-fan";
		tzp_governor_name = "pid_thermal_gov";

		dev1 {
			dev_data = "CPU-therm";
			coeffs = <30 0 0 0 0 0 0 0 0 0 0 0 0 0 0 0 0 0 0 0>;
		};
		dev2 {
			dev_data = "GPU-therm";
			coeffs = <30 0 0 0 0 0 0 0 0 0 0 0 0 0 0 0 0 0 0 0>;
		};
		dev3 {
			dev_data = "AUX-therm";
			coeffs = <40 0 0 0 0 0 0 0 0 0 0 0 0 0 0 0 0 0 0 0>;
		};
	};

	thermal-fan-est {
		compatible = "thermal-fan-est";
		name = "thermal-fan-est";
		status = "okay";
		num_resources = <0>;
		shared_data = <&thermal_fan_est_shared_data>;
		trip_length = <10>;
		profiles {
			default = "quiet";
			quiet {
				active_trip_temps = <0 50000 63000 72000 81000
						140000 150000 160000 170000 180000>;
				active_hysteresis = <0 18000 8000 8000 8000
						0 0 0 0 0>;
			};
			cool {
				active_trip_temps = <0 35000 53000 62000 73000
						140000 150000 160000 170000 180000>;
				active_hysteresis = <0 9000 8000 8000 9000
						0 0 0 0 0>;
			};
		};
	};
	
/* sdhc-configure */
	ufshci@2450000 {
		vcc-supply = <&p2822_vdd_sdmmc1_sw>;
		vccq-supply = <&p2888_spmic_ldo7>;
		vccq2-supply = <&p2888_spmic_sd2>;
		status = "disabled";
		nvidia,enable-hs-mode;
		nvidia,cd-gpios = <&tegra_aon_gpio TEGRA194_AON_GPIO(EE, 0) GPIO_ACTIVE_HIGH>;
		nvidia,cd-wakeup-capable;
	};

	sdhci@3400000 {
		vmmc-supply = <&p2822_vdd_sdmmc1_sw>;
		mmc-ocr-mask = <0x0>;
		cd-gpios = <&tegra_main_gpio TEGRA194_MAIN_GPIO(G, 7) 0>;
		nvidia,cd-wakeup-capable;
		nvidia,vmmc-always-on;
		status = "okay";
	};

	sdhci@3460000 {
		vmmc-supply = <&p2888_spmic_ldo3>;
		vqmmc-supply = <&p2888_spmic_sd2>;
		uhs-mask = <0x0>;
		nvidia,enable-hwcq;
		status = "okay";
	};

/* gpio-configure */
	gpio@c2f0000 {
		pex-refclk-sel-low {
			gpio-hog;
			output-low;
			gpios = <TEGRA194_AON_GPIO(AA, 5) 0>;
			label = "pex_refclk_sel_low";
			status = "disabled";
		};

		pex-refclk-sel-high {
			gpio-hog;
			output-high;
			gpios = <TEGRA194_AON_GPIO(AA, 5) 0>;
			label = "pex_refclk_sel_high";
			status = "disabled";
		};
	};

	gpio@2200000 {
		pcie-reg-enable {
			gpio-hog;
			gpios = <TEGRA194_MAIN_GPIO(Z, 2) GPIO_ACTIVE_HIGH
				 TEGRA194_MAIN_GPIO(A, 1) GPIO_ACTIVE_LOW>;
			label = "pcie-3v3-reg", "pcie-12v-reg";
			output-high;
			status = "okay";
		};
		
		wifi-enable {
			gpio-hog;
			output-high;
			gpios = <TEGRA194_MAIN_GPIO(G, 3) 0>;
			label = "wifi-enable";
			status = "okay";
		};
	};

	gpio-keys {
		compatible = "gpio-keys";
		gpio-keys,name = "gpio-keys";

		forcerecovery {
			label = "force-recovery";
			gpios = <&tegra_main_gpio TEGRA194_MAIN_GPIO(G, 0) GPIO_ACTIVE_LOW>;
			linux,code = <BTN_1>;
		};

		power_key {
			label = "power-key";
			gpios = <&tegra_aon_gpio TEGRA194_AON_GPIO(EE, 4) GPIO_ACTIVE_LOW>;
			linux,code = <KEY_POWER>;
			gpio-key,wakeup;
		};
	};

/* pcie-configure */
	pcie@14100000 {
		status = "okay";

		vddio-pex-ctl-supply = <&p2888_spmic_sd3>;
		nvidia,disable-aspm-states = <0xc>;
		nvidia,enable-power-down;
		nvidia,disable-clock-request;

		phys = <&p2u_0>;
		phy-names = "pcie-p2u-0";
		
		nvidia,max-speed = <2>;
	};

	pcie@14180000 {
		status = "okay";

		vddio-pex-ctl-supply = <&p2888_spmic_sd3>;
		nvidia,disable-aspm-states = <0xf>;
		nvidia,enable-power-down;
		nvidia,disable-clock-request;

		phys = <&p2u_2>,
		       <&p2u_3>,
		       <&p2u_4>,
		       <&p2u_5>;
		phy-names = "pcie-p2u-0", "pcie-p2u-1", "pcie-p2u-2", "pcie-p2u-3";
	};
	
	pcie@14140000 {
		status = "okay";

		vddio-pex-ctl-supply = <&p2888_spmic_sd3>;
		nvidia,disable-aspm-states = <0xf>;
		nvidia,enable-power-down;
		nvidia,disable-clock-request;

		phys = <&p2u_7>;
		phy-names = "pcie-p2u-0";
		
		nvidia,pex-wake = <&tegra_main_gpio TEGRA194_MAIN_GPIO(L, 2) GPIO_ACTIVE_HIGH>;
	};

	pcie@141a0000 {
		status = "disabled";

		vddio-pex-ctl-supply = <&p2888_spmic_sd3>;
		nvidia,disable-aspm-states = <0xf>;
		nvidia,enable-power-down;
		nvidia,disable-clock-request;

		phys = <&p2u_12>,
		       <&p2u_13>,
		       <&p2u_14>,
		       <&p2u_15>,
		       <&p2u_16>,
		       <&p2u_17>,
		       <&p2u_18>,
		       <&p2u_19>;
		phy-names = "pcie-p2u-0", "pcie-p2u-1", "pcie-p2u-2", "pcie-p2u-3",
					"pcie-p2u-4", "pcie-p2u-5", "pcie-p2u-6", "pcie-p2u-7";

		nvidia,plat-gpios =
			<&tegra_main_gpio TEGRA194_MAIN_GPIO(Z, 2) GPIO_ACTIVE_HIGH    /* 3V3 */
			 &tegra_main_gpio TEGRA194_MAIN_GPIO(A, 1) GPIO_ACTIVE_LOW     /* 12V */
		     /*&tegra_main_gpio TEGRA194_MAIN_GPIO(Y, 4) GPIO_ACTIVE_HIGH */ /* I2C */
			>;
	};

	pcie_ep@141a0000 {
		status = "disabled";

		vddio-pex-ctl-supply = <&p2888_spmic_sd3>;
		nvidia,disable-aspm-states = <0xf>;

		phys = <&p2u_12>,
			   <&p2u_13>, 
			   <&p2u_14>, 
			   <&p2u_15>,
			   <&p2u_16>, 
			   <&p2u_17>, 
			   <&p2u_18>, 
			   <&p2u_19>;
		phy-names = "pcie-p2u-0", "pcie-p2u-1", "pcie-p2u-2", "pcie-p2u-3",
					"pcie-p2u-4", "pcie-p2u-5", "pcie-p2u-6", "pcie-p2u-7";

		nvidia,pex-rst-gpio = <&tegra_main_gpio TEGRA194_MAIN_GPIO(GG, 1) GPIO_ACTIVE_LOW>;
	};	


/* net-configure */
    ether_qos@2490000 {
		vddio_sys_enet_bias-supply = <&battery_reg>;
		vddio_enet-supply = <&battery_reg>;
		phy_vdd_1v8-supply = <&p2888_spmic_sd2>;
		phy_ovdd_rgmii-supply = <&p2888_spmic_sd2>;
		phy_pllvdd-supply = <&battery_reg>;
		
		/* PTP_ref clock speed in MHz */
		nvidia,ptp_ref_clock_speed = <312500000>;
		/* rxq_enable_ctrl = <rx0 rx1 rx2 rx3>
		 * 0x0 = Not enabled, 0x1 = Enabled for AV
		 * 0x2 = Enabled for Legacy, 0x3 = Reserved
		 */
		nvidia,rxq_enable_ctrl = <2 2 2 2>;
		nvidia,queue_prio = <0 1 2 3>;

		nvidia,use_tagged_ptp;
		nvidia,ptp_dma_ch = <3>;

		nvidia,chan_napi_quota = <64 64 64 64>;
		nvidia,pause_frames = <0>; /*0=enable, 1=disable */
		nvidia,phy-reset-gpio = <&tegra_main_gpio TEGRA194_MAIN_GPIO(G, 5) 0>;
		nvidia,phy-max-frame-size = <16>;	/* size in kbytes */
		nvidia,eth_iso_enable = <1>; /*0=enable, 1=disable */
		phy-mode = "rgmii-id";
		phy-handle = <&phy0>;

		mdio {
			compatible = "nvidia,eqos-mdio";
			#address-cells = <1>;
			#size-cells = <0>;

			phy0: ethernet-phy@0 {
				reg = <0>;
				interrupt-parent = <&tegra_main_gpio>;
				interrupts = <TEGRA194_MAIN_GPIO(G, 4) IRQ_TYPE_LEVEL_LOW>;
				marvell,copper-mode;
				/* Setup LED[2] as interrupt pin (active low) */
				marvell,reg-init = <0x03 0x12 0x7fff 0x880>;
			};
		};
	};

	/* Need to enable wifi_en pin during boot for PCIe enumeration */
	bcmdhd_pcie_wlan {
		compatible = "android,bcmdhd_pcie_wlan";
		wlan-pwr-gpio = <&tegra_main_gpio TEGRA194_MAIN_GPIO(G, 3) 0>;
		fw_path = "/vendor/firmware/fw_bcmdhd_4356.bin";
		nv_path = "/vendor/firmware/nvram_4356.txt";
		status = "okay";
	};
	
	
};

#include "tegra194-RTX-Display-manager.dtsi"
#include "tegra194-RTX-plugin-manager.dtsi"

/ {
	firmware {
		android {
			compatible = "android,firmware";
			hardware = "jetson-xavier";
			vbmeta {
				compatible = "android,vbmeta";
				parts = "vbmeta,kernel,kernel-dtb,APP,vendor,SOS";
			};
			fstab {
				compatible = "android,fstab";
				vendor {
					compatible = "android,vendor";
					dev = "/dev/block/platform/3460000.sdhci/by-name/vendor";
					type = "ext4";
					mnt_flags = "ro";
					fsmgr_flags = "wait,avb";
				};
				odm {
					compatible = "android,odm";
					dev = "/dev/block/platform/3460000.sdhci/by-name/odm";
					type = "ext4";
					mnt_flags = "ro";
					fsmgr_flags = "wait,avb";
				};
			};
		};
	};

#if LINUX_VERSION >= 414
	psci {
		status = "okay";
	};

	cpus {
		CPU_CORE_POWER_STATES: cpu_core_power_states {
			C1: c1 {
				idle-state-name = "Clock gated";
			};

			C6: c6 {
				idle-state-name = "Virtual core powergate";
			};

			C7: c7 {
				idle-state-name = "Core powergate";
			};
		};

		cpu_cluster_power_states {
			cc6 {
				idle-state-name = "Cluster powergate";
			};
		};

		cpu_cluster_group_power_states {
			cg7 {
				idle-state-name = "Cluster group railgate";
			};
		};
	};
	
	/* Change hardware identifier for k4.14 ap_sanity test */
	firmware {
		android {
			hardware = "galen-k414";
		};
	};
#endif

};


